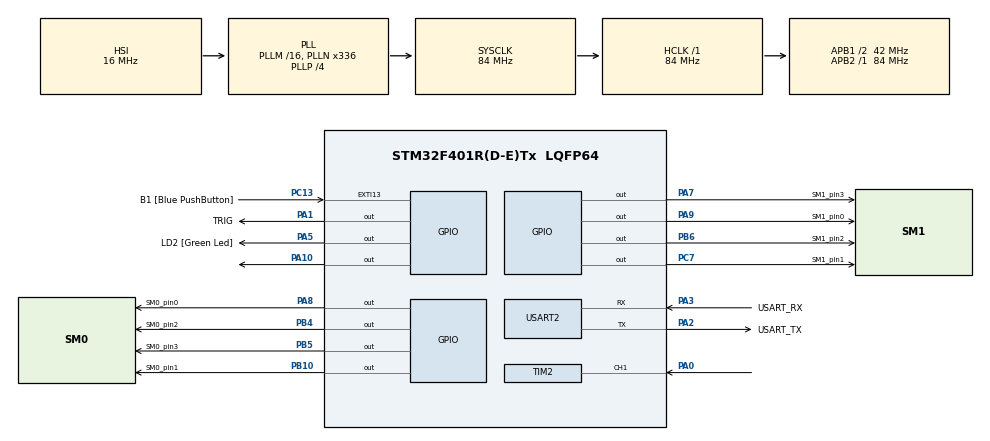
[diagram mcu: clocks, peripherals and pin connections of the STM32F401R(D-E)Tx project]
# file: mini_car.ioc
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FREERTOS.Tasks01=stepper_task,0,128,start_stepper_task,Default,NULL,Dynamic,NULL,NULL;ultrasonic_task,-3,128,start_ultrasonic_task,Default,NULL,Dynamic,NULL,NULL
FREERTOS.configUSE_TIMERS=1
Mcu.Family=STM32F4
Mcu.Name=STM32F401R(D-E)Tx
Mcu.Package=LQFP64
NVIC.PriorityGroup=NVIC_PRIORITYGROUP_4
NVIC.TIM1_UP_TIM10_IRQn=true\:0\:0\:false\:false\:true\:false\:false\:true
NVIC.TIM2_IRQn=true\:5\:0\:false\:false\:true\:true\:true\:true
NVIC.TIM3_IRQn=true\:5\:0\:false\:false\:true\:true\:true\:true
NVIC.TimeBase=TIM1_UP_TIM10_IRQn
NVIC.TimeBaseIP=TIM1
PA0-WKUP.Signal=S_TIM2_CH1_ETR
PA1.GPIO_Label=TRIG
PA1.Signal=GPIO_Output
PA10.Signal=GPIO_Output
PA13.GPIO_Label=TMS
PA13.Mode=Serial_Wire
PA13.Signal=SYS_JTMS-SWDIO
PA14.GPIO_Label=TCK
PA14.Mode=Serial_Wire
PA14.Signal=SYS_JTCK-SWCLK
PA2.GPIO_Label=USART_TX
PA2.GPIO_Mode=GPIO_MODE_AF_PP
PA2.GPIO_PuPd=GPIO_NOPULL
PA2.GPIO_Speed=GPIO_SPEED_FREQ_LOW
PA2.Mode=Asynchronous
PA2.Signal=USART2_TX
PA3.GPIO_Label=USART_RX
PA3.GPIO_Mode=GPIO_MODE_AF_PP
PA3.GPIO_PuPd=GPIO_NOPULL
PA3.GPIO_Speed=GPIO_SPEED_FREQ_LOW
PA3.Mode=Asynchronous
PA3.Signal=USART2_RX
PA5.GPIO_Label=LD2 [Green Led]
PA5.GPIO_Mode=GPIO_MODE_OUTPUT_PP
PA5.GPIO_PuPd=GPIO_NOPULL
PA5.GPIO_Speed=GPIO_SPEED_FREQ_LOW
PA5.Signal=GPIO_Output
PA7.GPIO_Label=SM1_pin3
PA7.Signal=GPIO_Output
PA8.GPIO_Label=SM0_pin0
PA8.GPIO_PuPd=GPIO_PULLDOWN
PA8.Signal=GPIO_Output
PA9.GPIO_Label=SM1_pin0
PA9.Signal=GPIO_Output
PB10.GPIO_Label=SM0_pin1
PB10.Signal=GPIO_Output
PB3.GPIO_Label=SWO
PB3.Signal=SYS_JTDO-SWO
PB4.GPIO_Label=SM0_pin2
PB4.Signal=GPIO_Output
PB5.GPIO_Label=SM0_pin3
PB5.Signal=GPIO_Output
PB6.GPIO_Label=SM1_pin2
PB6.Signal=GPIO_Output
PC13-ANTI_TAMP.GPIO_Label=B1 [Blue PushButton]
PC13-ANTI_TAMP.GPIO_ModeDefaultEXTI=GPIO_MODE_IT_FALLING
PC13-ANTI_TAMP.GPIO_PuPd=GPIO_NOPULL
PC13-ANTI_TAMP.Signal=GPXTI13
PC14-OSC32_IN.Mode=LSE-External-Oscillator
PC14-OSC32_IN.Signal=RCC_OSC32_IN
PC15-OSC32_OUT.Mode=LSE-External-Oscillator
PC15-OSC32_OUT.Signal=RCC_OSC32_OUT
PC7.GPIO_Label=SM1_pin1
PC7.Signal=GPIO_Output
PH0\ -\ OSC_IN.Mode=HSE-External-Clock-Source
PH0\ -\ OSC_IN.Signal=RCC_OSC_IN
PH1\ -\ OSC_OUT.Mode=HSE-External-Clock-Source
PH1\ -\ OSC_OUT.Signal=RCC_OSC_OUT
ProjectManager.HeapSize=0x200
ProjectManager.StackSize=0x400
ProjectManager.TargetToolchain=Makefile
RCC.48MHZClocksFreq_Value=48000000
RCC.AHBFreq_Value=84000000
RCC.APB1CLKDivider=RCC_HCLK_DIV2
RCC.APB1Freq_Value=42000000
RCC.APB1TimFreq_Value=84000000
RCC.APB2Freq_Value=84000000
RCC.APB2TimFreq_Value=84000000
RCC.CortexFreq_Value=84000000
RCC.HCLKFreq_Value=84000000
RCC.HSE_VALUE=8000000
RCC.HSI_VALUE=16000000
RCC.PLLN=336
RCC.PLLP=RCC_PLLP_DIV4
RCC.PLLQ=7
RCC.SYSCLKFreq_VALUE=84000000
RCC.SYSCLKSource=RCC_SYSCLKSOURCE_PLLCLK
RCC.VCOOutputFreq_Value=336000000
SH.S_TIM2_CH1_ETR.0=TIM2_CH1,Input_Capture1_from_TI1
TIM2.Channel-Input_Capture1_from_TI1=TIM_CHANNEL_1
TIM2.Prescaler=84-1
TIM3.Period=1000-1
TIM3.Prescaler=84-1
USART2.VirtualMode=VM_ASYNC
VP_FREERTOS_VS_CMSIS_V1.Mode=CMSIS_V1
VP_SYS_VS_tim1.Mode=TIM1
VP_TIM2_VS_ClockSourceINT.Mode=Internal
VP_TIM3_VS_ClockSourceINT.Mode=Internal
board=NUCLEO-F401RE

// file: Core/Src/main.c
/* USER CODE BEGIN Header */
/**
  ******************************************************************************
  * @file           : main.c
  * @brief          : Main program body
  ******************************************************************************
  * @attention
  *
  * <h2><center>&copy; Copyright (c) 2022 STMicroelectronics.
  * All rights reserved.</center></h2>
  *
  * This software component is licensed by ST under BSD 3-Clause license,
  * the "License"; You may not use this file except in compliance with the
  * License. You may obtain a copy of the License at:
  *                        opensource.org/licenses/BSD-3-Clause
  *
  ******************************************************************************
  */
/* USER CODE END Header */
#include "main.h"
#include "cmsis_os.h"

/* USER CODE BEGIN Includes */
#include "debug.h"
/* USER CODE END Includes */

TIM_HandleTypeDef htim2;
TIM_HandleTypeDef htim3;

UART_HandleTypeDef huart2;

osThreadId stepper_taskHandle;
osThreadId ultrasonic_taskHandle;

void SystemClock_Config(void);
static void MX_GPIO_Init(void);
static void MX_USART2_UART_Init(void);
static void MX_TIM2_Init(void);
static void MX_TIM3_Init(void);
void start_stepper_task(void const * argument);
void start_ultrasonic_task(void const * argument);

int main(void)
{

  /* MCU Configuration--------------------------------------------------------*/

  /* Reset of all peripherals, Initializes the Flash interface and the Systick. */
  HAL_Init();

  /* Configure the system clock */
  SystemClock_Config();

  /* Initialize all configured peripherals */
  MX_GPIO_Init();
  MX_USART2_UART_Init();
  MX_TIM2_Init();
  MX_TIM3_Init();
  /* USER CODE BEGIN 2 */

  stepper_motor_init_all();

  /* USER CODE END 2 */

  /* Create the thread(s) */
  /* definition and creation of stepper_task */
  osThreadDef(stepper_task, start_stepper_task, osPriorityNormal, 0, 128);
  stepper_taskHandle = osThreadCreate(osThread(stepper_task), NULL);

  /* definition and creation of ultrasonic_task */
  osThreadDef(ultrasonic_task, start_ultrasonic_task, osPriorityIdle, 0, 128);
  ultrasonic_taskHandle = osThreadCreate(osThread(ultrasonic_task), NULL);

  /* Start scheduler */
  osKernelStart();

  /* We should never get here as control is now taken by the scheduler */
  /* Infinite loop */
  while (1)
  {

  }
}

void SystemClock_Config(void)
{
  RCC_OscInitTypeDef RCC_OscInitStruct = {0};
  RCC_ClkInitTypeDef RCC_ClkInitStruct = {0};

  /** Configure the main internal regulator output voltage
  */
  __HAL_RCC_PWR_CLK_ENABLE();
  __HAL_PWR_VOLTAGESCALING_CONFIG(PWR_REGULATOR_VOLTAGE_SCALE2);
  /** Initializes the RCC Oscillators according to the specified parameters
  * in the RCC_OscInitTypeDef structure.
  */
  RCC_OscInitStruct.OscillatorType = RCC_OSCILLATORTYPE_HSI;
  RCC_OscInitStruct.HSIState = RCC_HSI_ON;
  RCC_OscInitStruct.HSICalibrationValue = RCC_HSICALIBRATION_DEFAULT;
  RCC_OscInitStruct.PLL.PLLState = RCC_PLL_ON;
  RCC_OscInitStruct.PLL.PLLSource = RCC_PLLSOURCE_HSI;
  RCC_OscInitStruct.PLL.PLLM = 16;
  RCC_OscInitStruct.PLL.PLLN = 336;
  RCC_OscInitStruct.PLL.PLLP = RCC_PLLP_DIV4;
  RCC_OscInitStruct.PLL.PLLQ = 7;
  if (HAL_RCC_OscConfig(&RCC_OscInitStruct) != HAL_OK)
  {
    Error_Handler();
  }
  /** Initializes the CPU, AHB and APB buses clocks
  */
  RCC_ClkInitStruct.ClockType = RCC_CLOCKTYPE_HCLK|RCC_CLOCKTYPE_SYSCLK
                              |RCC_CLOCKTYPE_PCLK1|RCC_CLOCKTYPE_PCLK2;
  RCC_ClkInitStruct.SYSCLKSource = RCC_SYSCLKSOURCE_PLLCLK;
  RCC_ClkInitStruct.AHBCLKDivider = RCC_SYSCLK_DIV1;
  RCC_ClkInitStruct.APB1CLKDivider = RCC_HCLK_DIV2;
  RCC_ClkInitStruct.APB2CLKDivider = RCC_HCLK_DIV1;

  if (HAL_RCC_ClockConfig(&RCC_ClkInitStruct, FLASH_LATENCY_2) != HAL_OK)
  {
    Error_Handler();
  }
}

static void MX_TIM2_Init(void)
{

  TIM_ClockConfigTypeDef sClockSourceConfig = {0};
  TIM_MasterConfigTypeDef sMasterConfig = {0};
  TIM_IC_InitTypeDef sConfigIC = {0};

  htim2.Instance = TIM2;
  htim2.Init.Prescaler = 84-1;
  htim2.Init.CounterMode = TIM_COUNTERMODE_UP;
  htim2.Init.Period = 4294967295;
  htim2.Init.ClockDivision = TIM_CLOCKDIVISION_DIV1;
  htim2.Init.AutoReloadPreload = TIM_AUTORELOAD_PRELOAD_DISABLE;
  if (HAL_TIM_Base_Init(&htim2) != HAL_OK)
  {
    Error_Handler();
  }
  sClockSourceConfig.ClockSource = TIM_CLOCKSOURCE_INTERNAL;
  if (HAL_TIM_ConfigClockSource(&htim2, &sClockSourceConfig) != HAL_OK)
  {
    Error_Handler();
  }
  if (HAL_TIM_IC_Init(&htim2) != HAL_OK)
  {
    Error_Handler();
  }
  sMasterConfig.MasterOutputTrigger = TIM_TRGO_RESET;
  sMasterConfig.MasterSlaveMode = TIM_MASTERSLAVEMODE_DISABLE;
  if (HAL_TIMEx_MasterConfigSynchronization(&htim2, &sMasterConfig) != HAL_OK)
  {
    Error_Handler();
  }
  sConfigIC.ICPolarity = TIM_INPUTCHANNELPOLARITY_RISING;
  sConfigIC.ICSelection = TIM_ICSELECTION_DIRECTTI;
  sConfigIC.ICPrescaler = TIM_ICPSC_DIV1;
  sConfigIC.ICFilter = 0;
  if (HAL_TIM_IC_ConfigChannel(&htim2, &sConfigIC, TIM_CHANNEL_1) != HAL_OK)
  {
    Error_Handler();
  }
  /* USER CODE BEGIN TIM2_Init 2 */
  HAL_TIM_IC_Start_IT(&htim2, TIM_CHANNEL_1);
  /* USER CODE END TIM2_Init 2 */

}

static void MX_TIM3_Init(void)
{

  TIM_ClockConfigTypeDef sClockSourceConfig = {0};
  TIM_MasterConfigTypeDef sMasterConfig = {0};

  htim3.Instance = TIM3;
  htim3.Init.Prescaler = 84-1;
  htim3.Init.CounterMode = TIM_COUNTERMODE_UP;
  htim3.Init.Period = 1000-1;
  htim3.Init.ClockDivision = TIM_CLOCKDIVISION_DIV1;
  htim3.Init.AutoReloadPreload = TIM_AUTORELOAD_PRELOAD_DISABLE;
  if (HAL_TIM_Base_Init(&htim3) != HAL_OK)
  {
    Error_Handler();
  }
  sClockSourceConfig.ClockSource = TIM_CLOCKSOURCE_INTERNAL;
  if (HAL_TIM_ConfigClockSource(&htim3, &sClockSourceConfig) != HAL_OK)
  {
    Error_Handler();
  }
  sMasterConfig.MasterOutputTrigger = TIM_TRGO_RESET;
  sMasterConfig.MasterSlaveMode = TIM_MASTERSLAVEMODE_DISABLE;
  if (HAL_TIMEx_MasterConfigSynchronization(&htim3, &sMasterConfig) != HAL_OK)
  {
    Error_Handler();
  }
  /* USER CODE BEGIN TIM3_Init 2 */
  HAL_TIM_Base_Start_IT(&htim3);
  /* USER CODE END TIM3_Init 2 */

}

static void MX_USART2_UART_Init(void)
{

  huart2.Instance = USART2;
  huart2.Init.BaudRate = 115200;
  huart2.Init.WordLength = UART_WORDLENGTH_8B;
  huart2.Init.StopBits = UART_STOPBITS_1;
  huart2.Init.Parity = UART_PARITY_NONE;
  huart2.Init.Mode = UART_MODE_TX_RX;
  huart2.Init.HwFlowCtl = UART_HWCONTROL_NONE;
  huart2.Init.OverSampling = UART_OVERSAMPLING_16;
  if (HAL_UART_Init(&huart2) != HAL_OK)
  {
    Error_Handler();
  }

}

static void MX_GPIO_Init(void)
{
  GPIO_InitTypeDef GPIO_InitStruct = {0};

  /* GPIO Ports Clock Enable */
  __HAL_RCC_GPIOC_CLK_ENABLE();
  __HAL_RCC_GPIOH_CLK_ENABLE();
  __HAL_RCC_GPIOA_CLK_ENABLE();
  __HAL_RCC_GPIOB_CLK_ENABLE();

  /*Configure GPIO pin Output Level */
  HAL_GPIO_WritePin(GPIOA, TRIG_Pin|LD2_Pin|SM1_pin3_Pin|SM0_pin0_Pin
                          |SM1_pin0_Pin|GPIO_PIN_10, GPIO_PIN_RESET);

  /*Configure GPIO pin Output Level */
  HAL_GPIO_WritePin(GPIOB, SM0_pin1_Pin|SM0_pin2_Pin|SM0_pin3_Pin|SM1_pin2_Pin, GPIO_PIN_RESET);

  /*Configure GPIO pin Output Level */
  HAL_GPIO_WritePin(SM1_pin1_GPIO_Port, SM1_pin1_Pin, GPIO_PIN_RESET);

  /*Configure GPIO pin : B1_Pin */
  GPIO_InitStruct.Pin = B1_Pin;
  GPIO_InitStruct.Mode = GPIO_MODE_IT_FALLING;
  GPIO_InitStruct.Pull = GPIO_NOPULL;
  HAL_GPIO_Init(B1_GPIO_Port, &GPIO_InitStruct);

  /*Configure GPIO pins : TRIG_Pin LD2_Pin SM1_pin3_Pin SM1_pin0_Pin
                           PA10 */
  GPIO_InitStruct.Pin = TRIG_Pin|LD2_Pin|SM1_pin3_Pin|SM1_pin0_Pin
                          |GPIO_PIN_10;
  GPIO_InitStruct.Mode = GPIO_MODE_OUTPUT_PP;
  GPIO_InitStruct.Pull = GPIO_NOPULL;
  GPIO_InitStruct.Speed = GPIO_SPEED_FREQ_LOW;
  HAL_GPIO_Init(GPIOA, &GPIO_InitStruct);

  /*Configure GPIO pins : SM0_pin1_Pin SM0_pin2_Pin SM0_pin3_Pin SM1_pin2_Pin */
  GPIO_InitStruct.Pin = SM0_pin1_Pin|SM0_pin2_Pin|SM0_pin3_Pin|SM1_pin2_Pin;
  GPIO_InitStruct.Mode = GPIO_MODE_OUTPUT_PP;
  GPIO_InitStruct.Pull = GPIO_NOPULL;
  GPIO_InitStruct.Speed = GPIO_SPEED_FREQ_LOW;
  HAL_GPIO_Init(GPIOB, &GPIO_InitStruct);

  /*Configure GPIO pin : SM1_pin1_Pin */
  GPIO_InitStruct.Pin = SM1_pin1_Pin;
  GPIO_InitStruct.Mode = GPIO_MODE_OUTPUT_PP;
  GPIO_InitStruct.Pull = GPIO_NOPULL;
  GPIO_InitStruct.Speed = GPIO_SPEED_FREQ_LOW;
  HAL_GPIO_Init(SM1_pin1_GPIO_Port, &GPIO_InitStruct);

  /*Configure GPIO pin : SM0_pin0_Pin */
  GPIO_InitStruct.Pin = SM0_pin0_Pin;
  GPIO_InitStruct.Mode = GPIO_MODE_OUTPUT_PP;
  GPIO_InitStruct.Pull = GPIO_PULLDOWN;
  GPIO_InitStruct.Speed = GPIO_SPEED_FREQ_LOW;
  HAL_GPIO_Init(SM0_pin0_GPIO_Port, &GPIO_InitStruct);

}

void start_stepper_task(void const * argument)
{
  /* USER CODE BEGIN 5 */

  /* Infinite loop */
  for(;;)
  {
    run_stepper_motor_task();
    osDelay(1);
  }
  /* USER CODE END 5 */
}

void start_ultrasonic_task(void const * argument)
{
  /* USER CODE BEGIN start_ultrasonic_task */
  /* Infinite loop */
  for(;;)
  {
    run_application_task();
    run_ultrasonic_task();
    osDelay(1);
  }
  /* USER CODE END start_ultrasonic_task */
}

 /**
  * @brief  Period elapsed callback in non blocking mode
  * @note   This function is called  when TIM1 interrupt took place, inside
  * HAL_TIM_IRQHandler(). It makes a direct call to HAL_IncTick() to increment
  * a global variable "uwTick" used as application time base.
  * @param  htim : TIM handle
  * @retval None
  */
void HAL_TIM_PeriodElapsedCallback(TIM_HandleTypeDef *htim)
{
  if (htim->Instance == TIM1) {
    HAL_IncTick();
  }
}

void Error_Handler(void)
{
  __disable_irq();
  while (1)
  {
  }
}

/************************ (C) COPYRIGHT STMicroelectronics *****END OF FILE****/
